# STM32F217 register map
File version: 1.2
CPU: CM3 r1p1, little endian, no MPU, no FPU, 4 interrupt priority bits
Registers are 32-bit, read-write, reset 0x0 unless marked. A register's access mark holds for its fields unless they carry their own. Offsets are from the block's base; [hi:lo] are bit positions.

## TIM10 — General-purpose-timers
Base 0x40014400
Same registers: TIM13 0x40001C00, TIM14 0x40002000, TIM11 0x40014800
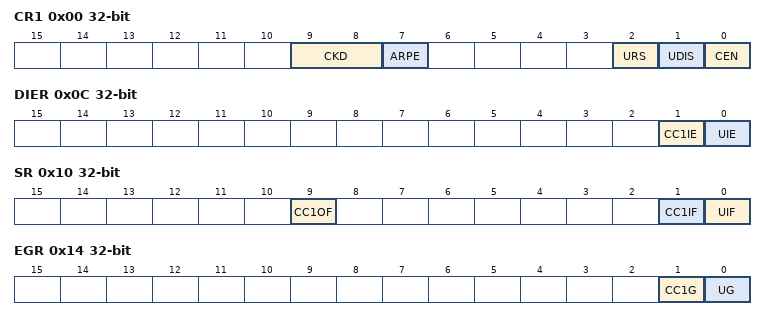
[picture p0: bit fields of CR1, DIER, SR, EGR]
0x00 CR1 — control register 1
  [9:8] CKD — Clock division
  [7] ARPE — Auto-reload preload enable
  [2] URS — Update request source
  [1] UDIS — Update disable
  [0] CEN — Counter enable
0x0C DIER — DMA/Interrupt enable register
  [1] CC1IE — Capture/Compare 1 interrupt enable
  [0] UIE — Update interrupt enable
0x10 SR — status register
  [9] CC1OF — Capture/Compare 1 overcapture flag
  [1] CC1IF — Capture/compare 1 interrupt flag
  [0] UIF — Update interrupt flag
0x14 EGR wo — event generation register
  [1] CC1G — Capture/compare 1 generation
  [0] UG — Update generation
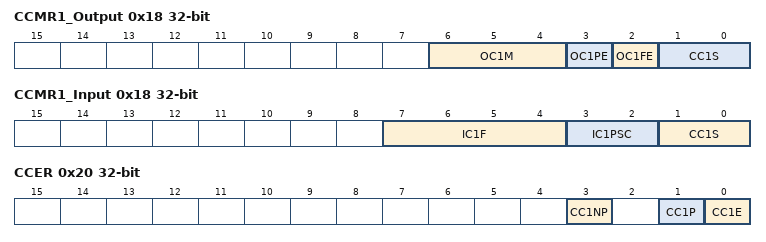
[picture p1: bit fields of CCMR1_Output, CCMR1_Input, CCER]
0x18 CCMR1_Output — capture/compare mode register (output mode)
  [6:4] OC1M — Output Compare 1 mode
  [3] OC1PE — Output Compare 1 preload enable
  [2] OC1FE — Output compare 1 fast enable
  [1:0] CC1S — Capture/Compare 1 selection
0x18 CCMR1_Input (alternate view of CCMR1_Output) — capture/compare mode register (input mode)
  [7:4] IC1F — Input capture 1 filter
  [3:2] IC1PSC — Input capture 1 prescaler
  [1:0] CC1S — Capture/Compare 1 selection
0x20 CCER — capture/compare enable register
  [3] CC1NP — Capture/Compare 1 output Polarity
  [1] CC1P — Capture/Compare 1 output Polarity
  [0] CC1E — Capture/Compare 1 output enable
0x24 CNT — counter
  [15:0] CNT — counter value
0x28 PSC — prescaler
  [15:0] PSC — Prescaler value
0x2C ARR — auto-reload register
  [15:0] ARR — Auto-reload value
0x34 CCR1 — capture/compare register 1
  [15:0] CCR1 — Capture/Compare 1 value
0x50 OR — option register
  [1:0] RMP — Input 1 remapping capability

## TIM6 — Basic-timers
Base 0x40001000
Same registers: TIM7 0x40001400
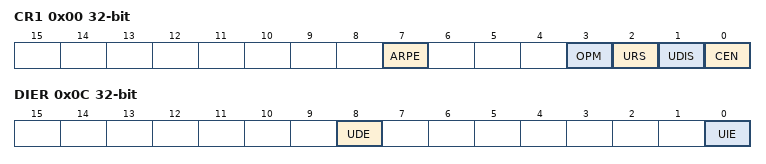
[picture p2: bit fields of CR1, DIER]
0x00 CR1 — control register 1
  [7] ARPE — Auto-reload preload enable
  [3] OPM — One-pulse mode
  [2] URS — Update request source
  [1] UDIS — Update disable
  [0] CEN — Counter enable
0x04 CR2 — control register 2
  [6:4] MMS — Master mode selection
0x0C DIER — DMA/Interrupt enable register
  [8] UDE — Update DMA request enable
  [0] UIE — Update interrupt enable
0x10 SR — status register
  [0] UIF — Update interrupt flag
0x14 EGR wo — event generation register
  [0] UG — Update generation
0x24 CNT — counter
  [15:0] CNT — Low counter value
0x28 PSC — prescaler
  [15:0] PSC — Prescaler value
0x2C ARR — auto-reload register
  [15:0] ARR — Low Auto-reload value

## Ethernet_MMC — Ethernet: MAC management counters
Base 0x40028100
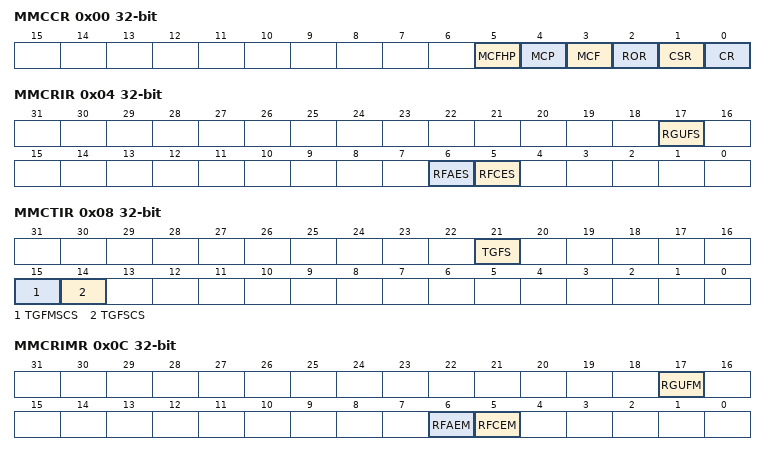
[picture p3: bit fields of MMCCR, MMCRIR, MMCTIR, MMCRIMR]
0x00 MMCCR — Ethernet MMC control register
  [5] MCFHP — MMC counter Full-Half preset
  [4] MCP — MMC counter preset
  [3] MCF — MMC counter freeze
  [2] ROR — Reset on read
  [1] CSR — Counter stop rollover
  [0] CR — Counter reset
0x04 MMCRIR — Ethernet MMC receive interrupt register
  [17] RGUFS — Received Good Unicast Frames Status
  [6] RFAES — Received frames alignment error status
  [5] RFCES — Received frames CRC error status
0x08 MMCTIR — Ethernet MMC transmit interrupt register
  [21] TGFS — Transmitted good frames status
  [15] TGFMSCS — Transmitted good frames more single collision status
  [14] TGFSCS — Transmitted good frames single collision status
0x0C MMCRIMR — Ethernet MMC receive interrupt mask register
  [17] RGUFM — Received good unicast frames mask
  [6] RFAEM — Received frames alignment error mask
  [5] RFCEM — Received frame CRC error mask
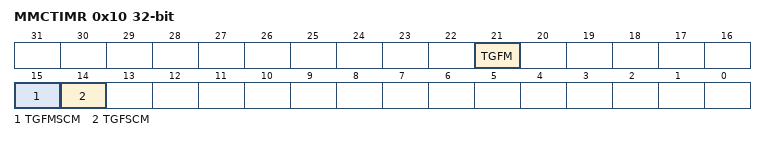
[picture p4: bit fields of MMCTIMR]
0x10 MMCTIMR — Ethernet MMC transmit interrupt mask register
  [21] TGFM — Transmitted good frames mask
  [15] TGFMSCM — Transmitted good frames more single collision mask
  [14] TGFSCM — Transmitted good frames single collision mask
0x4C MMCTGFSCCR ro — Ethernet MMC transmitted good frames after a single collision counter
  [31:0] TGFSCC — Transmitted good frames single collision counter
0x50 MMCTGFMSCCR ro — Ethernet MMC transmitted good frames after more than a single collision
  [31:0] TGFMSCC — Transmitted good frames more single collision counter
0x68 MMCTGFCR ro — Ethernet MMC transmitted good frames counter register
  [31:0] TGFC — Transmitted good frames counter
0x94 MMCRFCECR ro — Ethernet MMC received frames with CRC error counter register
  [31:0] RFCFC — Received frames CRC error counter
0x98 MMCRFAECR ro — Ethernet MMC received frames with alignment error counter register
  [31:0] RFAEC — Received frames alignment error counter
0xC4 MMCRGUFCR ro — MMC received good unicast frames counter register
  [31:0] RGUFC — Received good unicast frames counter
